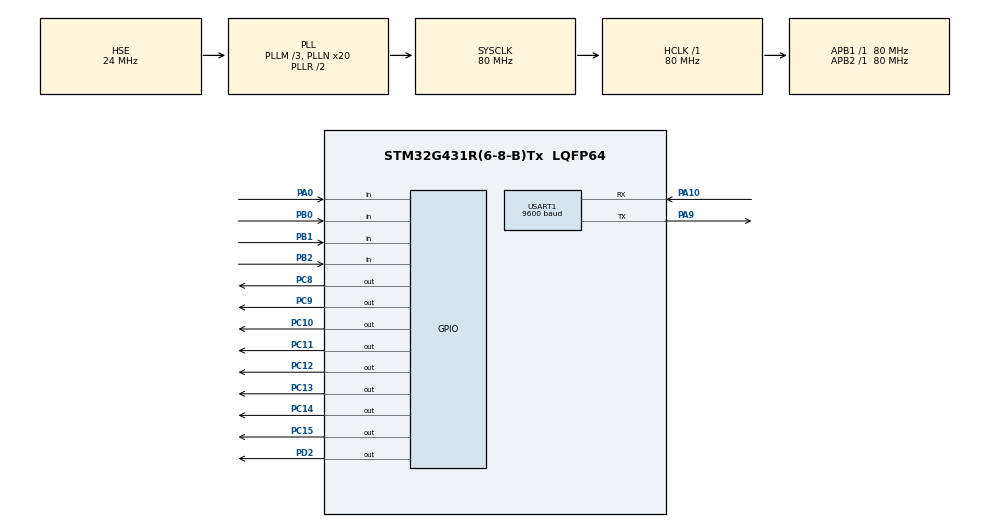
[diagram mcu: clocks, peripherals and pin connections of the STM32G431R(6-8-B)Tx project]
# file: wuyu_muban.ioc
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Dma.Request0=USART1_RX
Dma.Request1=USART1_TX
Dma.USART1_RX.0.Direction=DMA_PERIPH_TO_MEMORY
Dma.USART1_RX.0.EventEnable=DISABLE
Dma.USART1_RX.0.Instance=DMA1_Channel1
Dma.USART1_RX.0.MemDataAlignment=DMA_MDATAALIGN_BYTE
Dma.USART1_RX.0.MemInc=DMA_MINC_ENABLE
Dma.USART1_RX.0.Mode=DMA_NORMAL
Dma.USART1_RX.0.PeriphDataAlignment=DMA_PDATAALIGN_BYTE
Dma.USART1_RX.0.PeriphInc=DMA_PINC_DISABLE
Dma.USART1_RX.0.Polarity=HAL_DMAMUX_REQ_GEN_RISING
Dma.USART1_RX.0.Priority=DMA_PRIORITY_LOW
Dma.USART1_RX.0.RequestNumber=1
Dma.USART1_RX.0.SignalID=NONE
Dma.USART1_RX.0.SyncEnable=DISABLE
Dma.USART1_RX.0.SyncPolarity=HAL_DMAMUX_SYNC_NO_EVENT
Dma.USART1_RX.0.SyncRequestNumber=1
Dma.USART1_RX.0.SyncSignalID=NONE
Dma.USART1_TX.1.Direction=DMA_MEMORY_TO_PERIPH
Dma.USART1_TX.1.EventEnable=DISABLE
Dma.USART1_TX.1.Instance=DMA1_Channel2
Dma.USART1_TX.1.MemDataAlignment=DMA_MDATAALIGN_BYTE
Dma.USART1_TX.1.MemInc=DMA_MINC_ENABLE
Dma.USART1_TX.1.Mode=DMA_NORMAL
Dma.USART1_TX.1.PeriphDataAlignment=DMA_PDATAALIGN_BYTE
Dma.USART1_TX.1.PeriphInc=DMA_PINC_DISABLE
Dma.USART1_TX.1.Polarity=HAL_DMAMUX_REQ_GEN_RISING
Dma.USART1_TX.1.Priority=DMA_PRIORITY_LOW
Dma.USART1_TX.1.RequestNumber=1
Dma.USART1_TX.1.SignalID=NONE
Dma.USART1_TX.1.SyncEnable=DISABLE
Dma.USART1_TX.1.SyncPolarity=HAL_DMAMUX_SYNC_NO_EVENT
Dma.USART1_TX.1.SyncRequestNumber=1
Dma.USART1_TX.1.SyncSignalID=NONE
Mcu.Family=STM32G4
Mcu.Name=STM32G431R(6-8-B)Tx
Mcu.Package=LQFP64
NVIC.DMA1_Channel1_IRQn=true\:1\:0\:true\:false\:true\:false\:true\:true
NVIC.DMA1_Channel2_IRQn=true\:1\:0\:true\:false\:true\:false\:true\:true
NVIC.PriorityGroup=NVIC_PRIORITYGROUP_4
NVIC.TIM4_IRQn=true\:3\:0\:true\:false\:true\:true\:true\:true
NVIC.USART1_IRQn=true\:2\:0\:true\:false\:true\:true\:true\:true
PA0.GPIO_Mode=GPIO_MODE_INPUT
PA0.GPIO_PuPd=GPIO_PULLUP
PA0.Signal=GPIO_Input
PA10.GPIO_PuPd=GPIO_PULLUP
PA10.GPIO_Speed=GPIO_SPEED_FREQ_MEDIUM
PA10.Mode=Asynchronous
PA10.Signal=USART1_RX
PA13.Mode=Serial_Wire
PA13.Signal=SYS_JTMS-SWDIO
PA14.Mode=Serial_Wire
PA14.Signal=SYS_JTCK-SWCLK
PA9.GPIO_Speed=GPIO_SPEED_FREQ_MEDIUM
PA9.Mode=Asynchronous
PA9.Signal=USART1_TX
PB0.GPIO_Mode=GPIO_MODE_INPUT
PB0.GPIO_PuPd=GPIO_PULLUP
PB0.Signal=GPIO_Input
PB1.GPIO_Mode=GPIO_MODE_INPUT
PB1.GPIO_PuPd=GPIO_PULLUP
PB1.Signal=GPIO_Input
PB2.GPIO_Mode=GPIO_MODE_INPUT
PB2.GPIO_PuPd=GPIO_PULLUP
PB2.Signal=GPIO_Input
PC10.GPIO_ModeDefaultOutputPP=GPIO_MODE_OUTPUT_PP
PC10.PinState=GPIO_PIN_SET
PC10.Signal=GPIO_Output
PC11.GPIO_ModeDefaultOutputPP=GPIO_MODE_OUTPUT_PP
PC11.PinState=GPIO_PIN_SET
PC11.Signal=GPIO_Output
PC12.GPIO_ModeDefaultOutputPP=GPIO_MODE_OUTPUT_PP
PC12.PinState=GPIO_PIN_SET
PC12.Signal=GPIO_Output
PC13.GPIO_ModeDefaultOutputPP=GPIO_MODE_OUTPUT_PP
PC13.PinState=GPIO_PIN_SET
PC13.Signal=GPIO_Output
PC14-OSC32_IN.GPIO_ModeDefaultOutputPP=GPIO_MODE_OUTPUT_PP
PC14-OSC32_IN.PinState=GPIO_PIN_SET
PC14-OSC32_IN.Signal=GPIO_Output
PC15-OSC32_OUT.GPIO_ModeDefaultOutputPP=GPIO_MODE_OUTPUT_PP
PC15-OSC32_OUT.PinState=GPIO_PIN_SET
PC15-OSC32_OUT.Signal=GPIO_Output
PC8.GPIO_ModeDefaultOutputPP=GPIO_MODE_OUTPUT_PP
PC8.PinState=GPIO_PIN_SET
PC8.Signal=GPIO_Output
PC9.GPIO_ModeDefaultOutputPP=GPIO_MODE_OUTPUT_PP
PC9.PinState=GPIO_PIN_SET
PC9.Signal=GPIO_Output
PD2.GPIO_ModeDefaultOutputPP=GPIO_MODE_OUTPUT_PP
PD2.PinState=GPIO_PIN_SET
PD2.Signal=GPIO_Output
PF0-OSC_IN.Mode=HSE-External-Oscillator
PF0-OSC_IN.Signal=RCC_OSC_IN
PF1-OSC_OUT.Mode=HSE-External-Oscillator
PF1-OSC_OUT.Signal=RCC_OSC_OUT
ProjectManager.HeapSize=0x200
ProjectManager.StackSize=0x1000
ProjectManager.TargetToolchain=MDK-ARM V5.32
RCC.ADC12Freq_Value=80000000
RCC.AHBFreq_Value=80000000
RCC.APB1Freq_Value=80000000
RCC.APB1TimFreq_Value=80000000
RCC.APB2Freq_Value=80000000
RCC.APB2TimFreq_Value=80000000
RCC.CortexFreq_Value=80000000
RCC.EXTERNAL_CLOCK_VALUE=12288000
RCC.HCLKFreq_Value=80000000
RCC.HSE_VALUE=24000000
RCC.HSI48_VALUE=48000000
RCC.HSI_VALUE=16000000
RCC.LSE_VALUE=32768
RCC.PLLM=RCC_PLLM_DIV3
RCC.PLLN=20
RCC.PLLSourceVirtual=RCC_PLLSOURCE_HSE
RCC.SYSCLKFreq_VALUE=80000000
RCC.SYSCLKSource=RCC_SYSCLKSOURCE_PLLCLK
RCC.USBFreq_Value=80000000
RCC.VCOOutputFreq_Value=160000000
TIM4.PeriodNoDither=5000-1
TIM4.Prescaler=8000-1
USART1.BaudRate=9600
USART1.DMADisableonRxErrorParam=ADVFEATURE_DMA_DISABLEONRXERROR
USART1.OverrunDisableParam=ADVFEATURE_OVERRUN_DISABLE
USART1.VirtualMode-Asynchronous=VM_ASYNC
VP_SYS_VS_DBSignals.Mode=DisableDeadBatterySignals
VP_TIM4_VS_ClockSourceINT.Mode=Internal
board=custom

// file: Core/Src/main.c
/* USER CODE BEGIN Header */
/**
  ******************************************************************************
  * @file           : main.c
  * @brief          : Main program body
  ******************************************************************************
  * @attention
  *
  * Copyright (c) 2026 STMicroelectronics.
  * All rights reserved.
  *
  * This software is licensed under terms that can be found in the LICENSE file
  * in the root directory of this software component.
  * If no LICENSE file comes with this software, it is provided AS-IS.
  *
  ******************************************************************************
  */
/* USER CODE END Header */
#include "main.h"
#include "dma.h"
#include "tim.h"
#include "usart.h"
#include "gpio.h"

/* USER CODE BEGIN Includes */
#include "fun.h"
/* USER CODE END Includes */

void SystemClock_Config(void);

int main(void)
{

  /* MCU Configuration--------------------------------------------------------*/

  /* Reset of all peripherals, Initializes the Flash interface and the Systick. */
  HAL_Init();

  /* Configure the system clock */
  SystemClock_Config();

  /* USER CODE BEGIN SysInit */
   LCD_Init();
	 LCD_Clear(Black);
	 LCD_SetTextColor(White);
	 LCD_SetBackColor(Black);
  /* USER CODE END SysInit */

  /* Initialize all configured peripherals */
  MX_GPIO_Init();
  MX_DMA_Init();
  MX_USART1_UART_Init();
  MX_TIM4_Init();
  /* USER CODE BEGIN 2 */

  HAL_UARTEx_ReceiveToIdle_DMA(&huart1, uart_rx_str, 100);
	//启动定时器中断
  HAL_TIM_Base_Start_IT(&htim4);
//HAL_UART_Receive_IT(&huart1, uart_rx_str, 1);

  /* USER CODE END 2 */

  /* Infinite loop */
  /* USER CODE BEGIN WHILE */
  while (1)
  {
		loop();
    /* USER CODE END WHILE */

  }
}

void SystemClock_Config(void)
{
  RCC_OscInitTypeDef RCC_OscInitStruct = {0};
  RCC_ClkInitTypeDef RCC_ClkInitStruct = {0};

  /** Configure the main internal regulator output voltage
  */
  HAL_PWREx_ControlVoltageScaling(PWR_REGULATOR_VOLTAGE_SCALE1);

  /** Initializes the RCC Oscillators according to the specified parameters
  * in the RCC_OscInitTypeDef structure.
  */
  RCC_OscInitStruct.OscillatorType = RCC_OSCILLATORTYPE_HSE;
  RCC_OscInitStruct.HSEState = RCC_HSE_ON;
  RCC_OscInitStruct.PLL.PLLState = RCC_PLL_ON;
  RCC_OscInitStruct.PLL.PLLSource = RCC_PLLSOURCE_HSE;
  RCC_OscInitStruct.PLL.PLLM = RCC_PLLM_DIV3;
  RCC_OscInitStruct.PLL.PLLN = 20;
  RCC_OscInitStruct.PLL.PLLP = RCC_PLLP_DIV2;
  RCC_OscInitStruct.PLL.PLLQ = RCC_PLLQ_DIV2;
  RCC_OscInitStruct.PLL.PLLR = RCC_PLLR_DIV2;
  if (HAL_RCC_OscConfig(&RCC_OscInitStruct) != HAL_OK)
  {
    Error_Handler();
  }

  /** Initializes the CPU, AHB and APB buses clocks
  */
  RCC_ClkInitStruct.ClockType = RCC_CLOCKTYPE_HCLK|RCC_CLOCKTYPE_SYSCLK
                              |RCC_CLOCKTYPE_PCLK1|RCC_CLOCKTYPE_PCLK2;
  RCC_ClkInitStruct.SYSCLKSource = RCC_SYSCLKSOURCE_PLLCLK;
  RCC_ClkInitStruct.AHBCLKDivider = RCC_SYSCLK_DIV1;
  RCC_ClkInitStruct.APB1CLKDivider = RCC_HCLK_DIV1;
  RCC_ClkInitStruct.APB2CLKDivider = RCC_HCLK_DIV1;

  if (HAL_RCC_ClockConfig(&RCC_ClkInitStruct, FLASH_LATENCY_2) != HAL_OK)
  {
    Error_Handler();
  }
}

void Error_Handler(void)
{
  __disable_irq();
  while (1)
  {
  }
}
